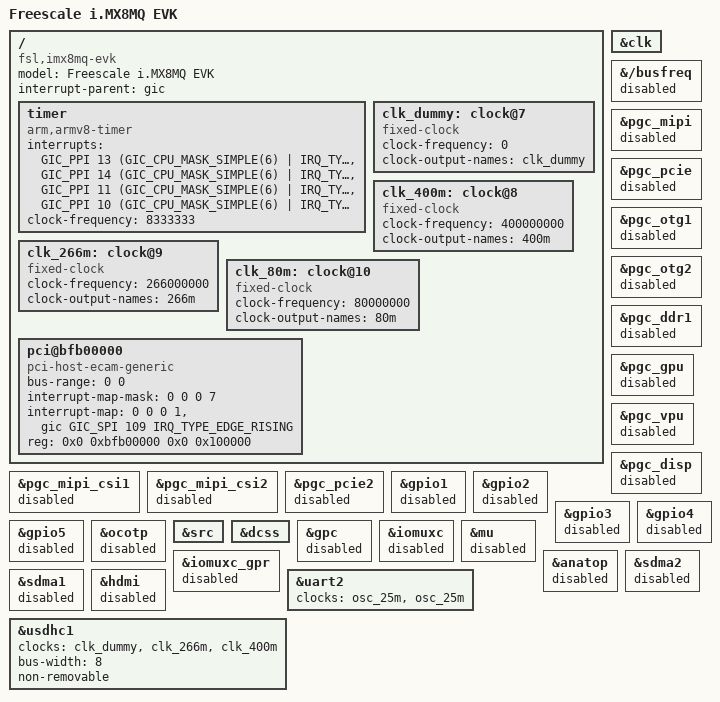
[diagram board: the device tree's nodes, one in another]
// SPDX-License-Identifier: (GPL-2.0+ OR MIT)
/*
 * Copyright 2019 NXP
 */

/dts-v1/;

#include "imx8mq.dtsi"

/ {
	model = "Freescale i.MX8MQ EVK";
	compatible = "fsl,imx8mq-evk", "fsl,imx8mq";
	interrupt-parent = <&gic>;

	timer {
		compatible = "arm,armv8-timer";
		interrupts = <GIC_PPI 13 (GIC_CPU_MASK_SIMPLE(6) | IRQ_TYPE_LEVEL_LOW)>, /* Physical Secure */
			     <GIC_PPI 14 (GIC_CPU_MASK_SIMPLE(6) | IRQ_TYPE_LEVEL_LOW)>, /* Physical Non-Secure */
			     <GIC_PPI 11 (GIC_CPU_MASK_SIMPLE(6) | IRQ_TYPE_LEVEL_LOW)>, /* Virtual */
			     <GIC_PPI 10 (GIC_CPU_MASK_SIMPLE(6) | IRQ_TYPE_LEVEL_LOW)>; /* Hypervisor */
		clock-frequency = <8333333>;
	};

	clk_dummy: clock@7 {
		compatible = "fixed-clock";
		#clock-cells = <0>;
		clock-frequency = <0>;
		clock-output-names = "clk_dummy";
	};

	/* The clocks are configured by 1st OS */
	clk_400m: clock@8 {
		compatible = "fixed-clock";
		#clock-cells = <0>;
		clock-frequency = <400000000>;
		clock-output-names = "400m";
	};
	clk_266m: clock@9 {
		compatible = "fixed-clock";
		#clock-cells = <0>;
		clock-frequency = <266000000>;
		clock-output-names = "266m";
	};
	clk_80m: clock@10 {
		compatible = "fixed-clock";
		#clock-cells = <0>;
		clock-frequency = <80000000>;
		clock-output-names = "80m";
	};

	pci@bfb00000 {
		compatible = "pci-host-ecam-generic";
		device_type = "pci";
		bus-range = <0 0>;
		#address-cells = <3>;
		#size-cells = <2>;
		#interrupt-cells = <1>;
		interrupt-map-mask = <0 0 0 7>;
		interrupt-map = <0 0 0 1 &gic GIC_SPI 109 IRQ_TYPE_EDGE_RISING>;
		reg = <0x0 0xbfb00000 0x0 0x100000>;
		ranges = <0x02000000 0x00 0x10000000 0x0 0x10000000 0x00 0x10000>;
	};
};

&clk {
	/delete-property/ compatible;
};

/delete-node/ &{/cpus/cpu@0};
/delete-node/ &{/cpus/cpu@1};
/delete-node/ &{/pmu};

&{/busfreq} {
	status = "disabled";
};

&pgc_mipi {
	status = "disabled";
};

&pgc_pcie {
	status = "disabled";
};

&pgc_otg1 {
	status = "disabled";
};

&pgc_otg2 {
	status = "disabled";
};

&pgc_ddr1 {
	status = "disabled";
};

&pgc_gpu {
	status = "disabled";
};

&pgc_vpu {
	status = "disabled";
};

&pgc_disp {
	status = "disabled";
};

&pgc_mipi_csi1 {
	status = "disabled";
};

&pgc_mipi_csi2 {
	status = "disabled";
};

&pgc_pcie2 {
	status = "disabled";
};

&gpio1 {
	status = "disabled";
};

&gpio2 {
	status = "disabled";
};

&gpio3 {
	status = "disabled";
};

&gpio4 {
	status = "disabled";
};

&gpio5 {
	status = "disabled";
};

/delete-node/ &tmu;
/delete-node/ &{/thermal-zones};

/delete-node/ &irqsteer;
&ocotp {
	/* not let imx8_soc_init hang system */
	/delete-property/ compatible;
	status = "disabled";
};
/delete-node/ &snvs;

&src {
	/delete-property/ compatible;
};

&dcss {
	/delete-property/ interrupt-parent;
	/delete-property/ interrupts;
	/delete-property/ interrupt-names;
};

&gpc {
	status = "disabled";
};

/delete-node/ &system_counter;
/*/delete-node/ &imx_ion;*/
/delete-node/ &pcie0;
/delete-node/ &pcie1;
/delete-node/ &vpu;
/delete-node/ &{/soc@0/ddr-pmu@3d800000};
/delete-node/ &rpmsg;
/delete-node/ &crypto;
/delete-node/ &caam_sm;
/delete-node/ &caam_snvs;
/delete-node/ &irq_sec_vio;
/delete-node/ &dma_apbh;
/delete-node/ &gpmi;

&iomuxc {
	status = "disabled";
};

&iomuxc_gpr {
	status = "disabled";
};

&mu {
	status = "disabled";
};

&anatop {
	status = "disabled";
};

&sdma2 {
	status = "disabled";
};

&sdma1 {
	status = "disabled";
};

&hdmi {
	status = "disabled";
};

&uart2 {
	clocks = <&osc_25m>,
		<&osc_25m>;
	clock-names = "ipg", "per";
	/delete-property/ dmas;
	/delete-property/ dmas-names;
	status = "okay";
};

&usdhc1 {
	clocks = <&clk_dummy>,
		<&clk_266m>,
		<&clk_400m>;
	/delete-property/assigned-clocks;
	/delete-property/assigned-clock-rates;
	clock-names = "ipg", "ahb", "per";
	bus-width = <8>;
	non-removable;
	status = "okay";
};
